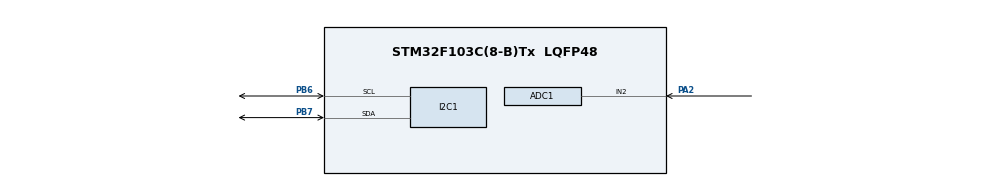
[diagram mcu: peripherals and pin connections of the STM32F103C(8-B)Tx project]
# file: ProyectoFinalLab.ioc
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ADC1.Channel-0\#ChannelRegularConversion=ADC_CHANNEL_2
ADC1.ContinuousConvMode=ENABLE
ADC1.NbrOfConversionFlag=1
ADC1.Rank-0\#ChannelRegularConversion=1
ADC1.SamplingTime-0\#ChannelRegularConversion=ADC_SAMPLETIME_1CYCLE_5
ADC1.master=1
Mcu.Family=STM32F1
Mcu.Name=STM32F103C(8-B)Tx
Mcu.Package=LQFP48
NVIC.PriorityGroup=NVIC_PRIORITYGROUP_4
PA13.Mode=Serial_Wire
PA13.Signal=SYS_JTMS-SWDIO
PA14.Mode=Serial_Wire
PA14.Signal=SYS_JTCK-SWCLK
PA2.Signal=ADCx_IN2
PB6.Mode=I2C
PB6.Signal=I2C1_SCL
PB7.Mode=I2C
PB7.Signal=I2C1_SDA
ProjectManager.HeapSize=0x200
ProjectManager.StackSize=0x400
ProjectManager.TargetToolchain=STM32CubeIDE
RCC.APB1Freq_Value=8000000
RCC.APB2Freq_Value=8000000
SH.ADCx_IN2.0=ADC1_IN2,IN2
board=custom

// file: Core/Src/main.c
/* USER CODE BEGIN Header */
/**
  ******************************************************************************
  * @file           : main.c
  * @brief          : Main program body
  ******************************************************************************
  * @attention
  *
  * Copyright (c) 2022 STMicroelectronics.
  * All rights reserved.
  *
  * This software is licensed under terms that can be found in the LICENSE file
  * in the root directory of this software component.
  * If no LICENSE file comes with this software, it is provided AS-IS.
  *
  ******************************************************************************
  */
/* USER CODE END Header */
#include "main.h"

 ADC_HandleTypeDef hadc1;

I2C_HandleTypeDef hi2c1;

void SystemClock_Config(void);
static void MX_GPIO_Init(void);
static void MX_ADC1_Init(void);
static void MX_I2C1_Init(void);

int main(void)
{
  /* USER CODE BEGIN 1 */

	uint16_t raw_data;
	uint16_t volt[4];
	uint16_t volt2[4];

  /* USER CODE END 1 */

  /* MCU Configuration--------------------------------------------------------*/

  /* Reset of all peripherals, Initializes the Flash interface and the Systick. */
  HAL_Init();

  /* Configure the system clock */
  SystemClock_Config();

  /* Initialize all configured peripherals */
  MX_GPIO_Init();
  MX_ADC1_Init();
  MX_I2C1_Init();
  /* USER CODE BEGIN 2 */

	  HAL_ADC_Start(&hadc1);           		 //ADC START

	  float V1;                        		  //Definir variable
	  float A1;
	  int A2=0, A3=0, A4=0;
	  int N=4;
	  float filtro;

  /* USER CODE END 2 */

  /* Infinite loop */
  /* USER CODE BEGIN WHILE */
  while (1)
  {
	  //inicio ADC
	 	  HAL_ADC_PollForConversion(&hadc1, HAL_MAX_DELAY);
	 	  raw_data = HAL_ADC_GetValue(&hadc1);
	 	  //fin adc

	 	  //valor voltaje sin filtrar
	 	 V1= (raw_data*3.3)/4011;

	 	 //inicio Mean average filter
	 	 A4=A3;
	 	 A3=A2;
	 	 A2=A1;
	 	 A1=V1;
	 	 filtro= (A1+A2+A3+A4)/N;

	 	 //fin filtro
	 	  //Envio de informacion a LCD

	 	  lcd_clear();  							//Limpiar la pantalla
	 	  	  HAL_Delay(1500);
	 	  	  lcd_init ();							//INITIALIZE THE LCD (** if the LCD is cleared, you need to initialize it again ***)

	 	  	  lcd_put_cur(0,0);
	 	  	  HAL_Delay(10);

	 	  	  lcd_send_string ("Volts [V]"); 		//se presenta en la pantalla LCD la palabra voltaje

	 	//Parte no filtrada LCD

	 	  	gcvt(V1, 4, volt); 						//v1:voltaje adquirido, 4:largo, volt:transformacion a palabra
	 	  	lcd_put_cur(1,2);
	 	  	lcd_send_string (volt);

	 	//Parte filtrada LCD

	 	  	gcvt(filtro, 4, volt2); 					//v1:voltaje adquirido, 4:largo, volt2:transformacion a palabra
	 		lcd_put_cur(1,11);
	 		lcd_send_string (volt2);
	 		HAL_Delay(1000);

	 	  	//Fin envio de informacion
    /* USER CODE END WHILE */

  }
}

void SystemClock_Config(void)
{
  RCC_OscInitTypeDef RCC_OscInitStruct = {0};
  RCC_ClkInitTypeDef RCC_ClkInitStruct = {0};
  RCC_PeriphCLKInitTypeDef PeriphClkInit = {0};

  /** Initializes the RCC Oscillators according to the specified parameters
  * in the RCC_OscInitTypeDef structure.
  */
  RCC_OscInitStruct.OscillatorType = RCC_OSCILLATORTYPE_HSI;
  RCC_OscInitStruct.HSIState = RCC_HSI_ON;
  RCC_OscInitStruct.HSICalibrationValue = RCC_HSICALIBRATION_DEFAULT;
  RCC_OscInitStruct.PLL.PLLState = RCC_PLL_NONE;
  if (HAL_RCC_OscConfig(&RCC_OscInitStruct) != HAL_OK)
  {
    Error_Handler();
  }

  /** Initializes the CPU, AHB and APB buses clocks
  */
  RCC_ClkInitStruct.ClockType = RCC_CLOCKTYPE_HCLK|RCC_CLOCKTYPE_SYSCLK
                              |RCC_CLOCKTYPE_PCLK1|RCC_CLOCKTYPE_PCLK2;
  RCC_ClkInitStruct.SYSCLKSource = RCC_SYSCLKSOURCE_HSI;
  RCC_ClkInitStruct.AHBCLKDivider = RCC_SYSCLK_DIV1;
  RCC_ClkInitStruct.APB1CLKDivider = RCC_HCLK_DIV1;
  RCC_ClkInitStruct.APB2CLKDivider = RCC_HCLK_DIV1;

  if (HAL_RCC_ClockConfig(&RCC_ClkInitStruct, FLASH_LATENCY_0) != HAL_OK)
  {
    Error_Handler();
  }
  PeriphClkInit.PeriphClockSelection = RCC_PERIPHCLK_ADC;
  PeriphClkInit.AdcClockSelection = RCC_ADCPCLK2_DIV2;
  if (HAL_RCCEx_PeriphCLKConfig(&PeriphClkInit) != HAL_OK)
  {
    Error_Handler();
  }
}

static void MX_ADC1_Init(void)
{

  ADC_ChannelConfTypeDef sConfig = {0};

  /** Common config
  */
  hadc1.Instance = ADC1;
  hadc1.Init.ScanConvMode = ADC_SCAN_DISABLE;
  hadc1.Init.ContinuousConvMode = ENABLE;
  hadc1.Init.DiscontinuousConvMode = DISABLE;
  hadc1.Init.ExternalTrigConv = ADC_SOFTWARE_START;
  hadc1.Init.DataAlign = ADC_DATAALIGN_RIGHT;
  hadc1.Init.NbrOfConversion = 1;
  if (HAL_ADC_Init(&hadc1) != HAL_OK)
  {
    Error_Handler();
  }

  /** Configure Regular Channel
  */
  sConfig.Channel = ADC_CHANNEL_2;
  sConfig.Rank = ADC_REGULAR_RANK_1;
  sConfig.SamplingTime = ADC_SAMPLETIME_1CYCLE_5;
  if (HAL_ADC_ConfigChannel(&hadc1, &sConfig) != HAL_OK)
  {
    Error_Handler();
  }

}

static void MX_I2C1_Init(void)
{

  hi2c1.Instance = I2C1;
  hi2c1.Init.ClockSpeed = 150000;
  hi2c1.Init.DutyCycle = I2C_DUTYCYCLE_2;
  hi2c1.Init.OwnAddress1 = 0;
  hi2c1.Init.AddressingMode = I2C_ADDRESSINGMODE_7BIT;
  hi2c1.Init.DualAddressMode = I2C_DUALADDRESS_DISABLE;
  hi2c1.Init.OwnAddress2 = 0;
  hi2c1.Init.GeneralCallMode = I2C_GENERALCALL_DISABLE;
  hi2c1.Init.NoStretchMode = I2C_NOSTRETCH_DISABLE;
  if (HAL_I2C_Init(&hi2c1) != HAL_OK)
  {
    Error_Handler();
  }

}

static void MX_GPIO_Init(void)
{

  /* GPIO Ports Clock Enable */
  __HAL_RCC_GPIOA_CLK_ENABLE();
  __HAL_RCC_GPIOB_CLK_ENABLE();

}

void Error_Handler(void)
{
  __disable_irq();
  while (1)
  {
  }
}
